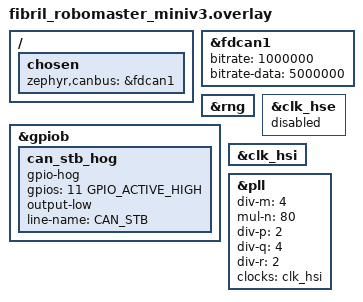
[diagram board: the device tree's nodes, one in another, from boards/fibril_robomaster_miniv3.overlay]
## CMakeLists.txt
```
# SPDX-License-Identifier: Apache-2.0
#
# Zephyr sample: fibril_can codegen-driven slave node.
#
# Runs fcan_codegen against fibril_can_example/schema/example_node.yaml and
# builds a Zephyr application around fcan_runtime + the C99 generated wrappers.
# The application publishes S2M telemetry on a Zephyr CAN device (native_sim
# uses zephyr,can-loopback) and prints state / TX / RX transitions.
#
# Prerequisites: see the fibril_can module's zephyr/cmake/fcan_invoke_codegen.cmake
# for the fcan_codegen CLI resolution, and the message it prints if the binary
# is not on PATH.

cmake_minimum_required(VERSION 3.20.0)
find_package(Zephyr REQUIRED HINTS $ENV{ZEPHYR_BASE})

project(fibril_can_example_node LANGUAGES C)

# The Zephyr module system exports ZEPHYR_FIBRIL_CAN_MODULE_DIR when the
# fibril_can module is on the west manifest — same variable the module's
# own zephyr/CMakeLists.txt uses (FCAN_ROOT).
if(NOT ZEPHYR_FIBRIL_CAN_MODULE_DIR)
  message(FATAL_ERROR
    "ZEPHYR_FIBRIL_CAN_MODULE_DIR is not set — is the fibril_can module on "
    "the west manifest and is CONFIG_FIBRIL_CAN=y?")
endif()

include(${ZEPHYR_FIBRIL_CAN_MODULE_DIR}/zephyr/cmake/fcan_invoke_codegen.cmake)

set(FCAN_EXAMPLE_SCHEMA
  "${ZEPHYR_FIBRIL_CAN_MODULE_DIR}/fibril_can_example/schema/example_node.yaml"
  CACHE FILEPATH "Schema YAML to feed into fcan_codegen")

fcan_invoke_codegen(
  SCHEMA     "${FCAN_EXAMPLE_SCHEMA}"
  OUTPUT_DIR "${CMAKE_CURRENT_BINARY_DIR}/schema_gen"
  BASE_NAME  schema_gen)

target_sources(app PRIVATE
  src/main.c
  src/app_logic.c
  src/rgb_state.c)

target_include_directories(app PRIVATE
  ${CMAKE_CURRENT_SOURCE_DIR}/src)
```

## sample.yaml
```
sample:
  name: fibril_can codegen slave node
  description: >-
    Bring up a fibril_can slave whose typed wrappers are generated at build
    time by fcan_codegen from the shared example schema. Uses zephyr,can-loopback
    on native_sim so the sample runs without extra hardware. Real deployments
    swap the DTS for an on-chip FDCAN controller.

tests:
  sample.lib.fibril_can.example_node:
    tags:
      - fibril_can
      - can
    # dt_chosen_enabled() gates on the base board providing a zephyr,canbus
    # chosen node. CONFIG_FIBRIL_CAN gates on the fibril_can module being on
    # the west manifest.
    filter: CONFIG_FIBRIL_CAN and dt_chosen_enabled("zephyr,canbus")
    harness: console
    harness_config:
      type: multi_line
      ordered: true
      regex:
        - "fcan_example_node: fcan_init OK"
        - "fcan_example_node: fcan_register_all OK"
        - "fcan_example_node: entering main loop"
    integration_platforms:
      - native_sim
      - fibril_robomaster_miniv1
      - fibril_robomaster_miniv3
      - fibril_robomaster_miniv4
    # Twister needs to know where fcan_codegen lives before it can build this
    # sample. Set FCAN_CODEGEN in the environment before invoking twister:
    #   FCAN_CODEGEN=/abs/path/fcan_codegen twister -T fibril_zephyr/samples/lib/fibril_can/example_node
    # or pass --extra-args=-DFCAN_CODEGEN=... to twister directly.
```

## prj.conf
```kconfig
# SPDX-License-Identifier: Apache-2.0

# --- fibril_can slave runtime
CONFIG_FIBRIL_CAN=y

# --- event-driven scheduler wake for fcan_zephyr_can_hal. main.c uses the
#     scheduler_wait / drain_rx / fcan_poll triple; wake bits are posted by
#     notify_tx_pending, RX enqueue, TX complete, and (as an app-owned bound
#     so app_logic_tick keeps its ~1 kHz cadence) a 1 kHz k_timer.
CONFIG_FCAN_ZEPHYR_EVENT_WAKE=y

# --- CAN driver + FD framing.
#     The per-driver MAX_FILTERS Kconfig defaults to 5 for zephyr,can-loopback
#     (see drivers/can/Kconfig.loopback). Two accept-all filters cover std +
#     ext, which fits comfortably. Real boards will need to bump the
#     corresponding CAN_<driver>_MAX_FILTERS in their board.conf.
CONFIG_CAN=y
CONFIG_CAN_FD_MODE=y

# --- entropy for boot_id (used as ID-conflict tiebreaker + T_listen jitter
#     seed). Real boards should have a hardware entropy source; the native_sim
#     shim (CONFIG_TEST_RANDOM_GENERATOR) is confined to boards/native_sim.conf
#     so it never leaks into a physical-board build.
CONFIG_ENTROPY_GENERATOR=y

# --- runtime allocation. K_HEAP_DEFINE in main.c carves its own arena, but
#     leave a small system heap in case the CAN driver / entropy driver
#     wants one.
CONFIG_HEAP_MEM_POOL_SIZE=4096

# --- stacks: main runs fcan_poll + app_logic + drains the RX msgq at 1 kHz.
CONFIG_MAIN_STACK_SIZE=4096

# --- logging: immediate so we see the state transitions live under native_sim.
CONFIG_LOG=y
CONFIG_LOG_MODE_IMMEDIATE=y
CONFIG_BOOT_BANNER=y
```

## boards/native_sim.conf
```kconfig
# SPDX-License-Identifier: Apache-2.0
#
# native_sim has no hardware entropy source. The fake_entropy driver, enabled
# by CONFIG_TEST_RANDOM_GENERATOR, gives sys_rand32_get() a predictable PRNG
# so the sample boots on this platform. Keep this OFF on real boards -- the
# boot_id used as an ID-conflict tiebreaker would become predictable.
CONFIG_TEST_RANDOM_GENERATOR=y
```

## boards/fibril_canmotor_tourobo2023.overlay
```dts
/*
 * SPDX-License-Identifier: Apache-2.0
 *
 * hub+latency-probe self+gs_usb sample on the Fibril RoboMaster Mini V1.
 *   external port (port 0) = USB FS (PA11/PA12) -> gs_usb subsys -> fcan_hub device
 *   peer port     (port 1) = FDCAN1 (PD0/PD1)   (board DTS already sets pinctrl + PLL_Q clock)
 *
 * Mirrors samples/lib/fibril_can/hub_gs_usb_self.overlay so both samples
 * share the same host udev/gs_usb setup — see that overlay's comments for
 * the HSI16/PLL rationale. Only the compatible strings and app source
 * differ between the two samples.
 */

/ {
	chosen {
		zephyr,canbus = &fdcan;
	};
};

&fdcan {
	/* 1 Mbps arbitration / 5 Mbps FD data phase — matches the single-bus
	 * latency_probe_node sample so wire timings are directly comparable. */
	bitrate = <1000000>;
	bitrate-data = <5000000>;
	status = "okay";
};

&rng {
	status = "okay";
};
```

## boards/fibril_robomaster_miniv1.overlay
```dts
/*
 * SPDX-License-Identifier: Apache-2.0
 *
 * fibril_can example_node bring-up on the Fibril RoboMaster Mini V1. The board
 * DTS already routes fdcan1 pinctrl to PD0/PD1 and sources its kernel clock
 * from PLL_Q (80 MHz); this overlay just enables the controller, picks a
 * bitrate, publishes it as zephyr,canbus, and turns on the on-chip RNG so
 * fcan_config_t::boot_id has a real entropy source.
 *
 * The board has no software-controlled CAN transceiver standby pin, so no
 * extra GPIO wiring is needed here.
 */

/ {
	chosen {
		zephyr,canbus = &fdcan1;
	};
};

&fdcan1 {
	status = "okay";

	/* 1 Mbps arbitration / 5 Mbps FD data phase. With PLL_Q @ 80 MHz that is
	 * 80 tq @ 1 Mbps and 16 tq @ 5 Mbps -- comfortable margin for the driver's
	 * default sample-point picks. If a deployment needs a different bitrate,
	 * change these two properties only.
	 */
	bitrate = <1000000>;
	bitrate-data = <5000000>;
};

/* sys_rand32_get() in the sample's main.c seeds fcan_config_t::boot_id. The
 * board DTS keeps CLK48_SEL on HSI48 already, so enabling the RNG node is all
 * the extra clocking it needs.
 */
&rng {
	status = "okay";
};
```

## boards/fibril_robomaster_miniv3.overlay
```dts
/*
 * SPDX-License-Identifier: Apache-2.0
 *
 * fibril_can example_node bring-up on the Fibril RoboMaster Mini V3. The board
 * DTS already routes fdcan1 pinctrl to PD0/PD1 (external CAN transceiver) and
 * sources its kernel clock from PLL_Q (80 MHz); this overlay just enables the
 * controller, picks a bitrate, publishes it as zephyr,canbus, and turns on the
 * on-chip RNG so fcan_config_t::boot_id has a real entropy source.
 *
 * Like miniv4, this revision wires a software-visible standby pin (STN=PB11)
 * to the external CAN transceiver. The Mbed target drives it low to exit
 * standby before any traffic, so we hog PB11 output-low here to keep the
 * transceiver in normal mode before the driver starts talking.
 */

/ {
	chosen {
		zephyr,canbus = &fdcan1;
	};
};

&fdcan1 {
	status = "okay";

	/* 1 Mbps arbitration / 5 Mbps FD data phase. With PLL_Q @ 80 MHz that is
	 * 80 tq @ 1 Mbps and 16 tq @ 5 Mbps -- comfortable margin for the driver's
	 * default sample-point picks. If a deployment needs a different bitrate,
	 * change these two properties only.
	 */
	bitrate = <1000000>;
	bitrate-data = <5000000>;
};

/* sys_rand32_get() in the sample's main.c seeds fcan_config_t::boot_id. The
 * board DTS keeps CLK48_SEL on HSI48 already, so enabling the RNG node is all
 * the extra clocking it needs.
 */
&rng {
	status = "okay";
};

&gpiob {
	can_stb_hog {
		gpio-hog;
		gpios = <11 GPIO_ACTIVE_HIGH>;
		output-low;
		line-name = "CAN_STB";
	};
};
&clk_hse {
	status = "disabled";
};

&clk_hsi {
	status = "okay";
};

&pll {
	div-m = <4>;
	mul-n = <80>;
	div-p = <2>;
	div-q = <4>;
	div-r = <2>;
	clocks = <&clk_hsi>;
	status = "okay";
};
```

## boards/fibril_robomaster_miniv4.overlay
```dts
/*
 * SPDX-License-Identifier: Apache-2.0
 *
 * fibril_can example_node bring-up on the Fibril RoboMaster Mini V4. The board
 * DTS already routes fdcan1 pinctrl to PD0/PD1 (external CAN transceiver) and
 * sources its kernel clock from PLL_Q (80 MHz); this overlay just enables the
 * controller, picks a bitrate and publishes it as zephyr,canbus. The board
 * also hogs the transceiver's standby pin (CAN_STB=PB11) low and enables the
 * on-chip RNG that seeds fcan_config_t::boot_id.
 */

/ {
	chosen {
		zephyr,canbus = &fdcan1;
	};
};

&fdcan1 {
	status = "okay";

	/* 1 Mbps arbitration / 5 Mbps FD data phase. With PLL_Q @ 80 MHz that is
	 * 80 tq @ 1 Mbps and 16 tq @ 5 Mbps -- comfortable margin for the driver's
	 * default sample-point picks. If a deployment needs a different bitrate,
	 * change these two properties only.
	 */
	bitrate = <1000000>;
	bitrate-data = <5000000>;
};

&clk_hse {
	status = "disabled";
};

&clk_hsi {
	status = "okay";
};

&pll {
	div-m = <4>;
	mul-n = <80>;
	div-p = <2>;
	div-q = <4>;
	div-r = <2>;
	clocks = <&clk_hsi>;
	status = "okay";
};
```

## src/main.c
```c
/*
 * SPDX-License-Identifier: Apache-2.0
 *
 * Zephyr entry point for the fibril_can codegen-driven slave sample.
 *
 * What the sample proves
 * ----------------------
 * 1. fcan_codegen produced schema_gen.{h,c} + schema_blob.c match the runtime
 *    ABI on the Zephyr target (no host-only assumptions leak in).
 * 2. fcan_init consumes the codegen's FCAN_* macros + apply_schema_capacities
 *    and returns FCAN_OK.
 * 3. fcan_register_all wires every topic/param/service without a link error
 *    — every user-implemented service handler in app_logic.c must be present
 *    or this file will fail to link.
 * 4. fcan_poll drives HEARTBEAT emissions and the state machine forward while
 *    the app_logic tick publishes S2M telemetry (visible via the HAL's
 *    tx_frames counter). A CAN master is not required for this to be a
 *    meaningful smoke test — SPEC §5.3 keeps the slave in UNPROVISIONED until
 *    an ANNOUNCE_ACK arrives, which never comes on a bare loopback bus.
 *
 * What the sample does NOT prove
 * ------------------------------
 * - Round-trip provisioning against fibril_can_bridge (needs vcan + a ROS 2
 *   bridge process; see docs/02-getting-started.md in the fibril_can repo).
 * - Timing correctness on real FDCAN hardware. can_loopback drops TX on the
 *   floor unless CAN_MODE_LOOPBACK is set, which we intentionally leave off
 *   to keep the state machine deterministic on native_sim.
 */

#include <stdint.h>
#include <string.h>

#include <zephyr/device.h>
#include <zephyr/drivers/can.h>
#include <zephyr/kernel.h>
#include <zephyr/logging/log.h>
#include <zephyr/random/random.h>

#include <fibril_can/fcan.h>
#include <fibril_can/fcan_protocol.h>

#include <fibril_can_zephyr/can_hal.h>

#include "schema_gen.h"
#include "app_logic.h"
#include "rgb_state.h"

/* The C emitter puts these symbols in schema_blob.c but doesn't declare them
 * in schema_gen.h — the C example does the same manual extern block. */
extern const uint8_t  fcan_schema_blob[];
extern const size_t   fcan_schema_blob_len;
extern const uint64_t fcan_schema_hash;

LOG_MODULE_REGISTER(fcan_example_node, LOG_LEVEL_INF);

#define CAN_NODE       DT_CHOSEN(zephyr_canbus)
#define CAN_BUS_DEV    DEVICE_DT_GET(CAN_NODE)

/* Default 0x10 keeps this sample self-contained; override without patching
 * the source by passing -DCONFIG_EXTRA_CFLAGS=-DNODE_ID=0x?? on the west
 * build line, or by adding the same via a board-specific overlay conf. */
#ifndef NODE_ID
#define NODE_ID        0x10
#endif
#define MASTER_LOST_US 300000U  /* §5.11 — 300 ms watchdog */

/* fcan_init calls the allocator once to carve every variable-length buffer
 * the runtime needs. Size the arena from a rough upper bound: 1 MotorDriver +
 * 1 Imu with service_buffer=0 fits comfortably in a few kilobytes; the extra
 * headroom absorbs future schema growth without a re-tune. */
K_HEAP_DEFINE(fcan_heap, 16 * 1024);

/* Enough slots for a burst of provisioning frames arriving faster than main
 * can drain them. Loss on overflow is preferable to blocking the CAN driver
 * thread, and the runtime tolerates dropped frames — masters retry. */
#define FCAN_RX_QUEUE_DEPTH 32
K_MSGQ_DEFINE(fcan_rx_msgq, sizeof(struct fcan_zephyr_can_rx_item), FCAN_RX_QUEUE_DEPTH, 4);

static void *heap_alloc(size_t size, size_t align, void *ctx)
{
	ARG_UNUSED(ctx);
	return k_heap_aligned_alloc(&fcan_heap, align, size, K_NO_WAIT);
}

/* Bounds scheduler_wait to ~1 ms so app_logic_tick keeps its documented
 * ~1 kHz cadence even when fcan has no closer runtime deadline (e.g.
 * UNPROVISIONED, where the ANNOUNCE cadence is much slower). Fires the
 * runtime's public TX-ready signal, which fcan_zephyr_can_hal wires to
 * k_event_post — ISR-safe, and coalesces cleanly with the wake bits already
 * posted by RX enqueue / TX complete / topic commit. */
static struct k_timer app_tick_timer;

static void app_tick_expiry(struct k_timer *timer)
{
	fcan_node_t *node = k_timer_user_data_get(timer);
	fcan_notify_tx_ready(node);
}

static const char *state_str(fcan_node_state_t s)
{
	switch (s) {
	case FCAN_STATE_UNPROVISIONED: return "UNPROVISIONED";
	case FCAN_STATE_PROVISIONED:   return "PROVISIONED";
	case FCAN_STATE_RUNNING:       return "RUNNING";
	case FCAN_STATE_FAULT:         return "FAULT";
	case FCAN_STATE_SUSPENDED:     return "SUSPENDED";
	default:                       return "?";
	}
}

int main(void)
{
	const struct device *can_dev = CAN_BUS_DEV;
	static struct fcan_zephyr_can_hal hal;

	if (!device_is_ready(can_dev)) {
		LOG_ERR("CAN device %s not ready", can_dev->name);
		return -ENODEV;
	}

	int rc = can_set_mode(can_dev, CAN_MODE_FD);
	if (rc != 0) {
		LOG_ERR("can_set_mode(FD) rc=%d", rc);
		return rc;
	}

	rc = fcan_zephyr_can_hal_init(&hal, can_dev, &fcan_rx_msgq);
	if (rc != 0) {
		return rc;
	}

	rc = can_start(can_dev);
	if (rc != 0) {
		LOG_ERR("can_start rc=%d", rc);
		return rc;
	}

	/* fcan_node_storage_size() is a runtime function (returns
	 * sizeof(fcan_node_t) — opaque on purpose), so we heap-allocate the
	 * node instead of trying to size a static array. 8-byte alignment
	 * satisfies the seqlock and u64-hash fields the runtime keeps inside. */
	fcan_node_t *node = k_heap_aligned_alloc(&fcan_heap, 8,
						 fcan_node_storage_size(),
						 K_NO_WAIT);
	if (node == NULL) {
		LOG_ERR("fcan_heap OOM allocating node (%u bytes)",
			(unsigned)fcan_node_storage_size());
		return -ENOMEM;
	}

	/* MotorDriver has max_count=4 in the schema; ship 1 instance to keep
	 * the RAM footprint small on native_sim. Imu is fixed count=1.
	 *
	 * Indexed by FCAN_ARRAY_*, never positionally: the block array order
	 * is derived from the schema, so a positional initialiser keeps
	 * compiling while handing a count to the wrong block.
	 */
	static const uint8_t counts[FCAN_NUM_BLOCK_ARRAYS] = {
		[FCAN_ARRAY_MOTORDRIVER] = 1U,
		[FCAN_ARRAY_IMU] = 1U,
	};

	fcan_config_t cfg = {
		.node_id = NODE_ID,
		.boot_id = sys_rand32_get(),
		.schema_blob = fcan_schema_blob,
		.schema_blob_len = (uint16_t)fcan_schema_blob_len,
		.schema_hash = fcan_schema_hash,
		.protocol_version = FCAN_PROTOCOL_VERSION,
		.block_count = FCAN_NUM_BLOCK_ARRAYS,
		.instance_counts = counts,
		.limits = {
			.max_frames = FCAN_MAX_FRAMES,
			.max_copy_entries = FCAN_MAX_COPY_ENTRIES,
			.service_buffer = FCAN_SERVICE_BUFFER,
			.service_reassembly = FCAN_SERVICE_REASSEMBLY,
			/* capacity fields filled below */
		},
		.hal = fcan_zephyr_can_hal_get(&hal),
		.allocator = {.alloc = heap_alloc, .ctx = NULL},
		.master_lost_us = MASTER_LOST_US,
		/* .t_listen_us = 0 -> runtime picks the safe default. */
	};
	fcan_apply_schema_capacities(&cfg.limits, counts);

	if (fcan_init(node, &cfg) != FCAN_OK) {
		LOG_ERR("fcan_init failed (fault=%d)", (int)fcan_fault(node));
		return -EIO;
	}
	LOG_INF("fcan_init OK: node_id=0x%02x schema_hash=0x%016llx blob_len=%u",
		cfg.node_id, (unsigned long long)fcan_schema_hash,
		(unsigned)fcan_schema_blob_len);

	if (fcan_register_all(node) != FCAN_OK) {
		LOG_ERR("fcan_register_all failed (fault=%d)", (int)fcan_fault(node));
		return -EIO;
	}
	LOG_INF("fcan_register_all OK");

	fcan_zephyr_can_hal_attach_node(&hal, node);

	app_logic_init();
	rgb_state_init();

	k_timer_init(&app_tick_timer, app_tick_expiry, NULL);
	k_timer_user_data_set(&app_tick_timer, node);
	k_timer_start(&app_tick_timer, K_MSEC(1), K_MSEC(1));

	LOG_INF("entering main loop (tick=1 ms, state=%s)",
		state_str(fcan_state(node)));

	fcan_node_state_t last_state = fcan_state(node);
	uint32_t last_log_ms = 0;
	uint32_t last_led_ms = 0;
	uint32_t last_tick_ms = k_uptime_get_32();
	while (true) {
		/* Event-driven wake triple: block on the HAL's k_event (posted
		 * by RX enqueue, TX complete, topic commit, plus the 1 kHz
		 * app_tick_timer above) or fcan's next runtime deadline,
		 * drain the RX msgq onto this thread so fcan_on_can_rx()
		 * never races fcan_poll(), then let fcan_poll() advance the
		 * state machine and TX scheduler. */
		fcan_zephyr_can_hal_scheduler_wait(&hal, node);
		fcan_zephyr_can_hal_drain_rx(&hal);
		fcan_poll(node);

		const uint32_t now_ms = k_uptime_get_32();
		/* app_logic_tick shares this thread with fcan_poll (app_logic.h
		 * contract) and expects ~1 kHz pacing. scheduler_wait can
		 * return more often on RX/TX bursts; gate on the ms boundary
		 * so bursts don't over-integrate the toy dynamics. */
		if ((int32_t)(now_ms - last_tick_ms) > 0) {
			app_logic_tick(0.001f);
			last_tick_ms = now_ms;
		}

		const fcan_node_state_t s = fcan_state(node);
		if (s != last_state) {
			LOG_INF("state: %s -> %s (fault=%d)",
				state_str(last_state), state_str(s),
				(int)fcan_fault(node));
			last_state = s;
		}

		/* LED indicator @ ~100 Hz. GPIO toggles at every 1 ms tick would
		 * be wasteful; the blink phase is derived from k_uptime so a
		 * coarser refresh does not slur the animation. */
		if ((now_ms - last_led_ms) >= 10U) {
			rgb_state_update(s, fcan_fault(node));
			last_led_ms = now_ms;
		}

		/* Heartbeat log so the sample provides an obvious "still alive"
		 * signal on a bus with no master. Rate-limit to once a second. */
		if ((now_ms - last_log_ms) >= 1000U) {
			LOG_INF("alive: state=%s tx=%u tx_drops=%u rx=%u",
				state_str(s), hal.tx_frames, hal.tx_drops,
				hal.rx_frames);
			last_log_ms = now_ms;
		}
	}
	/* unreachable */
}
```

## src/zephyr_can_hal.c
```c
/*
 * SPDX-License-Identifier: Apache-2.0
 *
 * See zephyr_can_hal.h for the design notes.
 */
#include "zephyr_can_hal.h"

#include <string.h>

#include <zephyr/logging/log.h>

LOG_MODULE_REGISTER(fcan_hal, LOG_LEVEL_INF);

static bool hal_send(uint32_t id, bool ext, const uint8_t *data, uint8_t len, void *ctx)
{
	struct zephyr_can_hal *h = ctx;

	/* CAN FD tops out at 64 B. can_bytes_to_dlc() has no defined behavior
	 * above that, so guard here rather than trusting it to clamp. */
	if (len > CANFD_MAX_DLEN) {
		LOG_ERR("send: oversize len=%u (max %u)", len, (unsigned)CANFD_MAX_DLEN);
		return false;
	}

	struct can_frame frame = {
		.id = id,
		/* BRS is set to allow the loopback and real FDCAN controllers to
		 * negotiate the fast-phase bit rate — the loopback ignores it,
		 * on real hardware it depends on the DTS bitrate-data setting. */
		.flags = CAN_FRAME_FDF | CAN_FRAME_BRS | (ext ? CAN_FRAME_IDE : 0U),
		.dlc = can_bytes_to_dlc(len),
	};
	memcpy(frame.data, data, len);
	/* can_bytes_to_dlc rounds up (e.g. 9 bytes -> DLC for 12). Zero-pad the
	 * tail so we do not leak stack contents to the wire. */
	const uint8_t dlc_bytes = can_dlc_to_bytes(frame.dlc);
	if (dlc_bytes > len) {
		memset(&frame.data[len], 0, dlc_bytes - len);
	}

	int rc = can_send(h->dev, &frame, K_NO_WAIT, NULL, NULL);
	if (rc == 0) {
		h->tx_frames++;
		return true;
	}
	/* -EAGAIN means the TX queue is full; the runtime's scheduler retries
	 * on the next fcan_poll tick. Anything else is a driver-level fault
	 * we surface via log. */
	h->tx_drops++;
	if (rc != -EAGAIN) {
		LOG_WRN("send: can_send rc=%d id=0x%x len=%u", rc, id, len);
	}
	return false;
}

static uint32_t hal_micros(void *ctx)
{
	ARG_UNUSED(ctx);
	/* Monotonic microseconds truncated to 32 bits. fcan_runtime takes
	 * differences modulo 2^32 so wraparound every ~71 minutes is fine. */
	return (uint32_t)k_ticks_to_us_floor64(k_uptime_ticks());
}

static void hal_rx_cb(const struct device *dev, struct can_frame *frame, void *user_data)
{
	ARG_UNUSED(dev);
	struct zephyr_can_hal *h = user_data;

	const uint8_t bytes = can_dlc_to_bytes(frame->dlc);
	if (bytes > sizeof(((struct fcan_rx_item){0}).data)) {
		LOG_WRN("rx: dropping oversize frame len=%u id=0x%x", bytes, frame->id);
		return;
	}

	struct fcan_rx_item item = {
		.id = frame->id,
		.len = bytes,
		.ext = (frame->flags & CAN_FRAME_IDE) != 0,
	};
	memcpy(item.data, frame->data, bytes);

	/* Drop rather than block: RX runs on the CAN driver's rx thread. If we
	 * cannot enqueue we prefer to lose a frame over stalling the driver. */
	int rc = k_msgq_put(h->rx_msgq, &item, K_NO_WAIT);
	if (rc == 0) {
		h->rx_frames++;
	} else {
		LOG_WRN("rx: msgq full, dropping id=0x%x", frame->id);
	}
}

int zephyr_can_hal_init(struct zephyr_can_hal *h,
			const struct device *dev,
			struct k_msgq *rx_msgq)
{
	memset(h, 0, sizeof(*h));
	h->dev = dev;
	h->rx_msgq = rx_msgq;

	/* Accept every 11-bit ID. */
	const struct can_filter accept_std = {.id = 0U, .mask = 0U, .flags = 0U};
	int fid = can_add_rx_filter(dev, hal_rx_cb, h, &accept_std);
	if (fid < 0) {
		LOG_ERR("can_add_rx_filter (std) rc=%d", fid);
		return fid;
	}
	/* And every 29-bit ID — SPEC §5 uses extended IDs throughout. */
	const struct can_filter accept_ext = {
		.id = 0U, .mask = 0U, .flags = CAN_FILTER_IDE,
	};
	fid = can_add_rx_filter(dev, hal_rx_cb, h, &accept_ext);
	if (fid < 0) {
		LOG_ERR("can_add_rx_filter (ext) rc=%d", fid);
		return fid;
	}
	return 0;
}

void zephyr_can_hal_attach_node(struct zephyr_can_hal *h, fcan_node_t *node)
{
	h->node = node;
}

fcan_hal_t zephyr_can_hal_get(struct zephyr_can_hal *h)
{
	return (fcan_hal_t){
		.send = hal_send,
		.micros = hal_micros,
		.ctx = h,
	};
}

void zephyr_can_hal_drain_rx(struct zephyr_can_hal *h)
{
	if (h->node == NULL) {
		return; /* pre-fcan_init: the runtime cannot accept frames yet. */
	}

	struct fcan_rx_item item;
	while (k_msgq_get(h->rx_msgq, &item, K_NO_WAIT) == 0) {
		fcan_on_can_rx(h->node, item.id, item.ext, item.data, item.len);
	}
}
```

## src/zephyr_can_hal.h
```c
/*
 * SPDX-License-Identifier: Apache-2.0
 *
 * Zephyr CAN driver <-> fcan_hal_t bridge for the fibril_can example node.
 *
 * The HAL owns two responsibilities that live on opposite sides of the
 * kernel boundary:
 *   1. TX: fcan_runtime calls hal.send() from thread context (fcan_poll or a
 *      service handler) — we forward each call to can_send() with FD framing.
 *   2. RX: the CAN driver invokes our rx callback from a driver-owned thread
 *      (for zephyr,can-loopback it's the tx_thread; on real controllers it's
 *      typically a workqueue). fcan_on_can_rx() is safe from ISR but is not
 *      re-entrant against fcan_poll(). Instead of adding a lock we drop the
 *      frame into a k_msgq and let main() drain it right before fcan_poll().
 */
#ifndef ZEPHYR_CAN_HAL_H_
#define ZEPHYR_CAN_HAL_H_

#include <stdbool.h>
#include <stdint.h>

#include <zephyr/device.h>
#include <zephyr/drivers/can.h>
#include <zephyr/kernel.h>

#include <fibril_can/fcan.h>
#include <fibril_can/fcan_hal.h>

/* One queued frame — mirrors the fcan_on_can_rx() argument set so we don't
 * hold on to the driver's struct can_frame past the callback return. */
struct fcan_rx_item {
	uint32_t id;
	uint8_t  data[64];
	uint8_t  len;
	bool     ext;
};

struct zephyr_can_hal {
	const struct device *dev;
	fcan_node_t *node; /* set after fcan_init via zephyr_can_hal_attach_node() */
	struct k_msgq *rx_msgq;
	uint32_t tx_frames;
	uint32_t tx_drops;
	uint32_t rx_frames;
};

/* Prepare the HAL and register accept-all RX filters (standard + extended).
 * The caller owns the k_msgq so it can size / place it (a static
 * K_MSGQ_DEFINE next to main() is the expected usage).
 *
 * Returns 0 on success, or a negative errno mirroring the failing CAN API. */
int zephyr_can_hal_init(struct zephyr_can_hal *h,
			const struct device *dev,
			struct k_msgq *rx_msgq);

/* Post fcan_init: hand the runtime node to the HAL so fcan_on_can_rx() can
 * be dispatched from main() when the msgq is drained. */
void zephyr_can_hal_attach_node(struct zephyr_can_hal *h, fcan_node_t *node);

/* Vtable snapshot to hand to fcan_config_t.hal. */
fcan_hal_t zephyr_can_hal_get(struct zephyr_can_hal *h);

/* Drain the RX queue into fcan_on_can_rx(). Non-blocking. */
void zephyr_can_hal_drain_rx(struct zephyr_can_hal *h);

#endif /* ZEPHYR_CAN_HAL_H_ */
```
